AUTOSAR XML (schema 00050)
package /ComponentTypes
  swc implementation SWC_PLT_Appl_IoHwAb_Implementation: behavior=SWC_PLT_Appl_IoHwAb_InternalBehavior
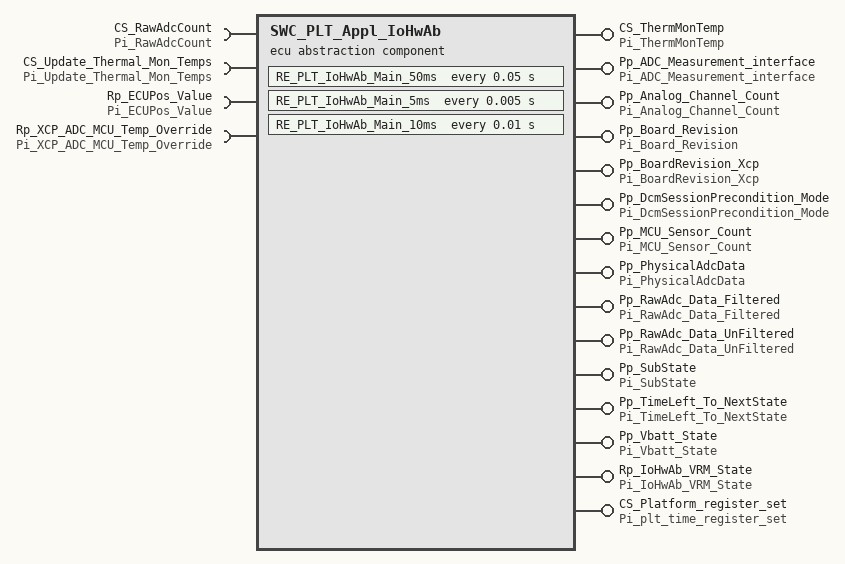
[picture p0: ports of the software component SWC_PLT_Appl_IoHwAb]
  ecu abstraction sw component type SWC_PLT_Appl_IoHwAb
    14 x provide port:
      CS_ThermMonTemp: server-com-spec{operation=Read, queue-length=1}, provided-interface=Pi_ThermMonTemp
      Pp_ADC_Measurement_interface: nonqueued-sender-com-spec{data-element=Element, init-value=constant-reference=C_ADC_Measurementinterface_T}, provided-interface=Pi_ADC_Measurement_interface
      Pp_Analog_Channel_Count: nonqueued-sender-com-spec{data-element=De_Analog_Channel_Count, init-value=0}, provided-interface=Pi_Analog_Channel_Count
      Pp_Board_Revision: nonqueued-sender-com-spec{data-element=De_Board_Revision, init-value=85}, provided-interface=Pi_Board_Revision
      Pp_BoardRevision_Xcp: nonqueued-sender-com-spec{data-element=De_BoardRevision_Xcp, init-value=0}, provided-interface=Pi_BoardRevision_Xcp
      Pp_DcmSessionPrecondition_Mode: mode-switch-sender-com-spec{mode-group=De_DcmSessionPrecondition_Mode, queue-length=1}, provided-interface=Pi_DcmSessionPrecondition_Mode
      Pp_MCU_Sensor_Count: nonqueued-sender-com-spec{data-element=De_MCU_Sensor_Count, init-value=0}, provided-interface=Pi_MCU_Sensor_Count
      Pp_PhysicalAdcData: nonqueued-sender-com-spec{data-element=De_PhysicalAdcData, init-value=fields=[Adc_Board_Rev:0, Adc_Batt_Volt:0, Adc_Pos_Gnd_A:0, Adc_Pos_Gnd_B:0, Adc_Pos_Gnd_C:0, Adc_Pos_Gnd_D:0, Adc_Eth_0v9:0, Adc_Rdi_Detect:0, Adc_MMIC_Temp:0, Adc_Mcu_Temp:0, Validity_Flag:0]}, provided-interface=Pi_PhysicalAdcData
      Pp_RawAdc_Data_Filtered: nonqueued-sender-com-spec{data-element=De_RawAdcData, init-value=fields=[Adc_Board_Rev:0, Adc_Batt_Volt:0, Adc_Pos_Gnd_A:0, Adc_Pos_Gnd_B:0, Adc_Pos_Gnd_C:0, Adc_Pos_Gnd_D:0, Adc_Eth_0v9:0, Adc_Rdi_Detect:0, Adc_MMIC_Temp:0, Adc_Mcu_Temp:0, Validity_Flag:0, Pos_Validity_Flag:0]}, provided-interface=Pi_RawAdc_Data_Filtered
      Pp_RawAdc_Data_UnFiltered: nonqueued-sender-com-spec{data-element=RawAdcDataUnfiltered, init-value=fields=[Adc_Board_Rev:0, Adc_Batt_Volt:0, Adc_Pos_Gnd_A:0, Adc_Pos_Gnd_B:0, Adc_Pos_Gnd_C:0, Adc_Pos_Gnd_D:0, Adc_Eth_0v9:0, Adc_Rdi_Detect:0, Adc_MMIC_Temp:0, Adc_Mcu_Temp:0, Validity_Flag:0]}, provided-interface=Pi_RawAdc_Data_UnFiltered
      Pp_SubState: nonqueued-sender-com-spec{data-element=De_SubState, init-value=0}, provided-interface=Pi_SubState
      Pp_TimeLeft_To_NextState: nonqueued-sender-com-spec{data-element=De_TimeLeft_To_NextState, init-value=0}, provided-interface=Pi_TimeLeft_To_NextState
      Pp_Vbatt_State: nonqueued-sender-com-spec{data-element=De_Vbatt_State, init-value=0}, provided-interface=Pi_Vbatt_State
      Rp_IoHwAb_VRM_State: nonqueued-sender-com-spec{data-element=De_VBattState_T, init-value=0}, provided-interface=Pi_IoHwAb_VRM_State
    4 x require port:
      CS_RawAdcCount: client-com-spec=Read, required-interface=Pi_RawAdcCount
      CS_Update_Thermal_Mon_Temps: client-com-spec=Read, required-interface=Pi_Update_Thermal_Mon_Temps
      Rp_ECUPos_Value: nonqueued-receiver-com-spec{data-element=De_ECUPos_Value, filter=data-filter-type=ALWAYS, init-value=0}, required-interface=Pi_ECUPos_Value
      Rp_XCP_ADC_MCU_Temp_Override: nonqueued-receiver-com-spec{data-element=De_XCP_ADC_MCU_Temp_Override, filter=data-filter-type=ALWAYS, init-value=1}, required-interface=Pi_XCP_ADC_MCU_Temp_Override
    provide port CS_Platform_register_set: server-com-spec{operation=fault_type, queue-length=1}, provided-interface=Pi_plt_time_register_set
    behavior SWC_PLT_Appl_IoHwAb_InternalBehavior: handle-termination-and-restart=NO-SUPPORT
      operation invoked event OIT_CS_Platform_register_set_Operation_CS_Platform_register_set_Operation: start-on-event=CS_Platform_register_set, operation=CS_Platform_register_set.fault_type
      operation invoked event OIT_CS_ThermMonTemp_Read_CS_ThermMonTemp_Read: start-on-event=CS_ThermMonTemp_Read, operation=CS_ThermMonTemp.Read
      init event SWC_PLT_Appl_IoHwAb_InitEvent: start-on-event=RE_PLT_IoHwAb_Init
      timing event TMT_RE_IoHwAb_Main_50ms: start-on-event=RE_PLT_IoHwAb_Main_50ms, period=0.05
      timing event TMT_RE_IoHwAb_Main_5ms: start-on-event=RE_PLT_IoHwAb_Main_5ms, period=0.005
      timing event TMT_RE_PLT_IoHwAb_Main_10ms: start-on-event=RE_PLT_IoHwAb_Main_10ms, period=0.01
      per-instance-parameters:
        parameter data prototype ECU_Position_ROMDefault: sw-calibration-access=READ-WRITE, type=Dt_EcuPosition_T, init-value=fields=[ECUPosition_Value:255, Reserved:0, CRC_Value:0]
      port-api-options:
        enable-take-address=false, error-handling=NO-TRANSFORMER-ERROR-HANDLING, indirect-api=false, port=Pp_PhysicalAdcData
        enable-take-address=false, error-handling=NO-TRANSFORMER-ERROR-HANDLING, indirect-api=false, port=Pp_RawAdc_Data_Filtered
        enable-take-address=false, error-handling=NO-TRANSFORMER-ERROR-HANDLING, indirect-api=false, port=Rp_ECUPos_Value
      6 x runnable:
        CS_Platform_register_set: can-be-invoked-concurrently=true
        CS_ThermMonTemp_Read: can-be-invoked-concurrently=true
        RE_PLT_IoHwAb_Init  # This will initialize all static variables in this SWC
          data-receive-point-by-arguments:
            access REC_Rp_ECUPos_Value_De_ECUPos_Value: accessed-variable=Rp_ECUPos_Value.De_ECUPos_Value
          data-send-points:
            access SEND_Pp_ADC_Measurement_interface_Element: accessed-variable=Pp_ADC_Measurement_interface.Element
            access SEND_Pp_Board_Revision_De_Board_Revision: accessed-variable=Pp_Board_Revision.De_Board_Revision
            access SEND_Pp_BoardRevision_Xcp_De_BoardRevision_Xcp: accessed-variable=Pp_BoardRevision_Xcp.De_BoardRevision_Xcp
        RE_PLT_IoHwAb_Main_50ms  # All the functionalities which are related to 50 ms shall be called here.
          data-receive-point-by-arguments:
            access REC_Rp_XCP_ADC_MCU_Temp_Override_De_XCP_ADC_MCU_Temp_Override: accessed-variable=Rp_XCP_ADC_MCU_Temp_Override.De_XCP_ADC_MCU_Temp_Override
          data-send-points:
            7 x access:
              SEND_Pp_MCU_Sensor_Count_De_MCU_Sensor_Count: accessed-variable=Pp_MCU_Sensor_Count.De_MCU_Sensor_Count
              SEND_Pp_SubState_De_SubState: accessed-variable=Pp_SubState.De_SubState
              SEND_Pp_TimeLeft_To_NextState_De_TimeLeft_To_NextState: accessed-variable=Pp_TimeLeft_To_NextState.De_TimeLeft_To_NextState
              SEND_Pp_Vbatt_State_De_Vbatt_State: accessed-variable=Pp_Vbatt_State.De_Vbatt_State
              SEND_Pp_RawAdc_Data_UnFiltered_RawAdcDataUnfiltered: accessed-variable=Pp_RawAdc_Data_UnFiltered.RawAdcDataUnfiltered
              SEND_Pp_RawAdc_Data_Filtered_De_RawAdcData: accessed-variable=Pp_RawAdc_Data_Filtered.De_RawAdcData
              SEND_Pp_PhysicalAdcData_De_PhysicalAdcData: accessed-variable=Pp_PhysicalAdcData.De_PhysicalAdcData
          mode switch point SWITCH_Pp_DcmSessionPrecondition_Mode_De_DcmSessionPrecondition_Mode: mode-group=Pp_DcmSessionPrecondition_Mode.De_DcmSessionPrecondition_Mode
          sync call SC_CS_Update_Thermal_Mon_Temps_Read: operation=CS_Update_Thermal_Mon_Temps.Read, timeout=0
        RE_PLT_IoHwAb_Main_5ms  # All the functionalities which are related to 5 ms shall be called here.
          data-receive-point-by-arguments:
            access REC_Rp_XCP_ADC_MCU_Temp_Override_De_XCP_ADC_MCU_Temp_Override: accessed-variable=Rp_XCP_ADC_MCU_Temp_Override.De_XCP_ADC_MCU_Temp_Override
          data-send-points:
            4 x access:
              SEND_Pp_Analog_Channel_Count_De_Analog_Channel_Count: accessed-variable=Pp_Analog_Channel_Count.De_Analog_Channel_Count
              SEND_Pp_PhysicalAdcData_De_PhysicalAdcData: accessed-variable=Pp_PhysicalAdcData.De_PhysicalAdcData
              SEND_Pp_RawAdc_Data_De_RawAdcData: accessed-variable=Pp_RawAdc_Data_Filtered.De_RawAdcData
              SEND_Pp_RawAdc_Data_UnFiltered_RawAdcDataUnfiltered: accessed-variable=Pp_RawAdc_Data_UnFiltered.RawAdcDataUnfiltered
          sync call SC_CS_RawAdcCount_Read: operation=CS_RawAdcCount.Read, timeout=0
        RE_PLT_IoHwAb_Main_10ms
